# WB32F10x register map
File version: 1.2
CPU: CM3 r2p0, little endian, MPU, no FPU, 4 interrupt priority bits
Registers are 32-bit, read-write, reset 0x0 unless marked. A register's access mark holds for its fields unless they carry their own. Offsets are from the block's base; [hi:lo] are bit positions.

## SPIS1 — Serial Peripheral Interface slave 1
Base 0x40003400
Same registers: SPIS2 0x40009400
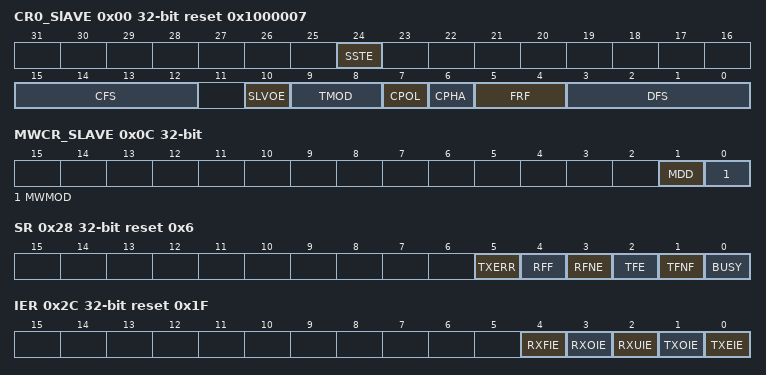
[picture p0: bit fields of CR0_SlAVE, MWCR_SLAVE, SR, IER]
0x00 CR0_SlAVE reset 0x1000007 — Control register 0 for slave
  [24] SSTE — SSN state
  [15:12] CFS — Control frame size
  [10] SLVOE — Slave output enable
  [9:8] TMOD — Transfer mode
  [7] CPOL — Clock polarity
  [6] CPHA — Clock phase
  [5:4] FRF — Frame format protocol select
  [3:0] DFS — Data frame size
0x08 SPIENR — SPI enable register
  [0] SPI_EN — SPI enable
0x0C MWCR_SLAVE — Microwire control register for slave
  [1] MDD — Microwire date transfer mode
  [0] MWMOD — Microwire mode
0x18 TXFTLR — Transmit FIFO threshold register
  [1:0] TFT — Transmit FIFO threshold
0x1C RXFTLR — Receive FIFO threshold register
  [1:0] RFT — Receive FIFO threshold
0x20 TXFLR ro — Transmit buffer state register
  [2:0] TXTFL — Date length of transmit FIFO
0x24 RXFLR ro — Receive buffer state register
  [2:0] RXTFL — Date length of receive FIFO
0x28 SR ro reset 0x6 — Status register
  [5] TXERR — Transmit error when transmit FIFO is empty
  [4] RFF — Receive FIFO full
  [3] RFNE — Receive FIFO not empty
  [2] TFE — Transmit FIFO empty
  [1] TFNF — Transmit FIFO not full
  [0] BUSY — Busy status
0x2C IER reset 0x1F — Interrupt enable register
  [4] RXFIE — Receive FIFO full interrupt enable
  [3] RXOIE — Receive FIFO overflow interrupt enable
  [2] RXUIE — Receive FIFO underflow interrupt enable
  [1] TXOIE — Transmit FIFO overflow interrupt enable
  [0] TXEIE — Transmit FIFO empty interrupt enable
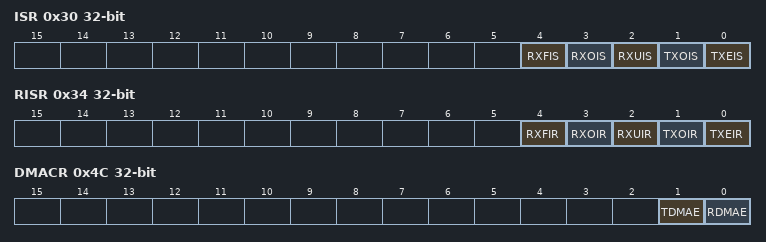
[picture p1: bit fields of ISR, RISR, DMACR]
0x30 ISR ro — Interrupt status register
  [4] RXFIS — Receive FIFO full interrupt status
  [3] RXOIS — Receive FIFO overflow interrupt status
  [2] RXUIS — Receive FIFO underflow interrupt status
  [1] TXOIS — Transmit FIFO overflow interrupt status
  [0] TXEIS — Transmit FIFO empty interrupt status
0x34 RISR ro — Raw interrupt status register
  [4] RXFIR — Receive FIFO full interrupt raw status
  [3] RXOIR — Receive FIFO overflow interrupt raw status
  [2] RXUIR — Receive FIFO underflow interrupt raw status
  [1] TXOIR — Transmit FIFO overflow interrupt raw status
  [0] TXEIR — Transmit FIFO empty interrupt raw status
0x38 TXOICR ro — Transmit FIFO overflow interrupt clear register
  [0] TXOICR — Clear transmit FIFO overflow interrupt
0x3C RXOICR ro — Receive FIFO overflow interrupt clear register
  [0] RXOICR — Clear receive FIFO overflow interrupt
0x40 RXUICR ro — Receive FIFO underflow interrupt clear register
  [0] RXUICR — Clear receive FIFO underflow interrupt
0x48 ICR ro — Interrupt clear register
  [0] ICR — Clear transmit FIFO overflow, receive FIFO overflow and underflow interrupt
0x4C DMACR — DMA control register
  [1] TDMAE — Transmit DMA enable
  [0] RDMAE — Receive DMA enable
0x50 DMATDLR — DMA transmit threshold register
  [1:0] DMATDLR — DMA transmit threshold
0x54 DMARDLR — DMA receive threshold register
  [1:0] DMARDLR — DMA receive threshold
0x60 DR — Data register
  [15:0] DR — SPI data

## SPIM2 — Serial Peripheral Interface master 2
Base 0x40009000
Registers as SPIS1, without CR0_SlAVE, MWCR_SLAVE; these are added or differ:
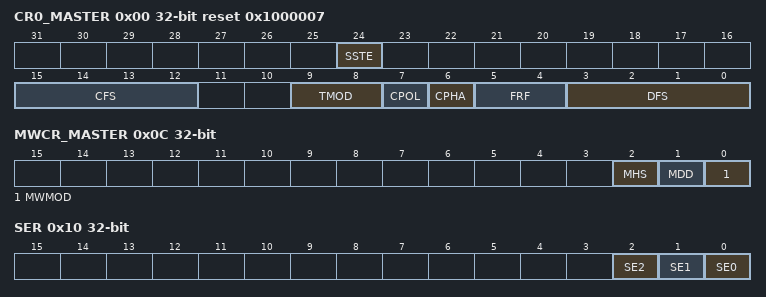
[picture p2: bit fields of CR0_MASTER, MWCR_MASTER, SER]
0x00 CR0_MASTER reset 0x1000007 (alternate view of CR0_SLAVE) — Control register 0 for master
  [24] SSTE — SSN state
  [15:12] CFS — Control frame size
  [9:8] TMOD — Transfer mode
  [7] CPOL — Clock polarity
  [6] CPHA — Clock phase
  [5:4] FRF — Frame format protocol select
  [3:0] DFS — Data frame size
0x04 CR1 — Control register 1
  [15:0] NDF — Number of max data frame
0x0C MWCR_MASTER (alternate view of MWCR_SLAVE) — Microwire control register for master
  [2] MHS — Microwire handshake
  [1] MDD — Microwire date transfer mode
  [0] MWMOD — Microwire mode
0x10 SER — Slave selection register
  [2] SE2 — Select slave 2
  [1] SE1 — Select slave 1
  [0] SE0 — Select slave 0
0x14 BAUDR — Baud rate register
  [15:0] SCKDV — SCLK division

## QSPI — Queue Serial peripheral interface controller
Base 0x40003000
Registers as SPIM2, without CR0_MASTER, MWCR_MASTER; these are added or differ:
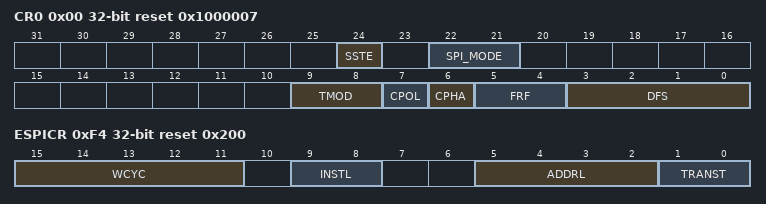
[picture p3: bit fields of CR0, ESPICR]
0x00 CR0 reset 0x1000007 — Control register 0
  [24] SSTE — SSN state
  [22:21] SPI_MODE
  [9:8] TMOD — Transfer mode
  [7] CPOL — Clock polarity
  [6] CPHA — Clock phase
  [5:4] FRF — Frame format protocol select
  [3:0] DFS — Data frame size
0x08 SPIENR — SPI enable register
  [0] SPI_EN — QSPI enable
0x60 DR — Data register
  [15:0] DR — QSPI data
0xF4 ESPICR reset 0x200 — Enhance SPI control register
  [15:11] WCYC — Wait cycle
  [9:8] INSTL — Instruction length
  [5:2] ADDRL — Address length
  [1:0] TRANST — Transmit frame format
